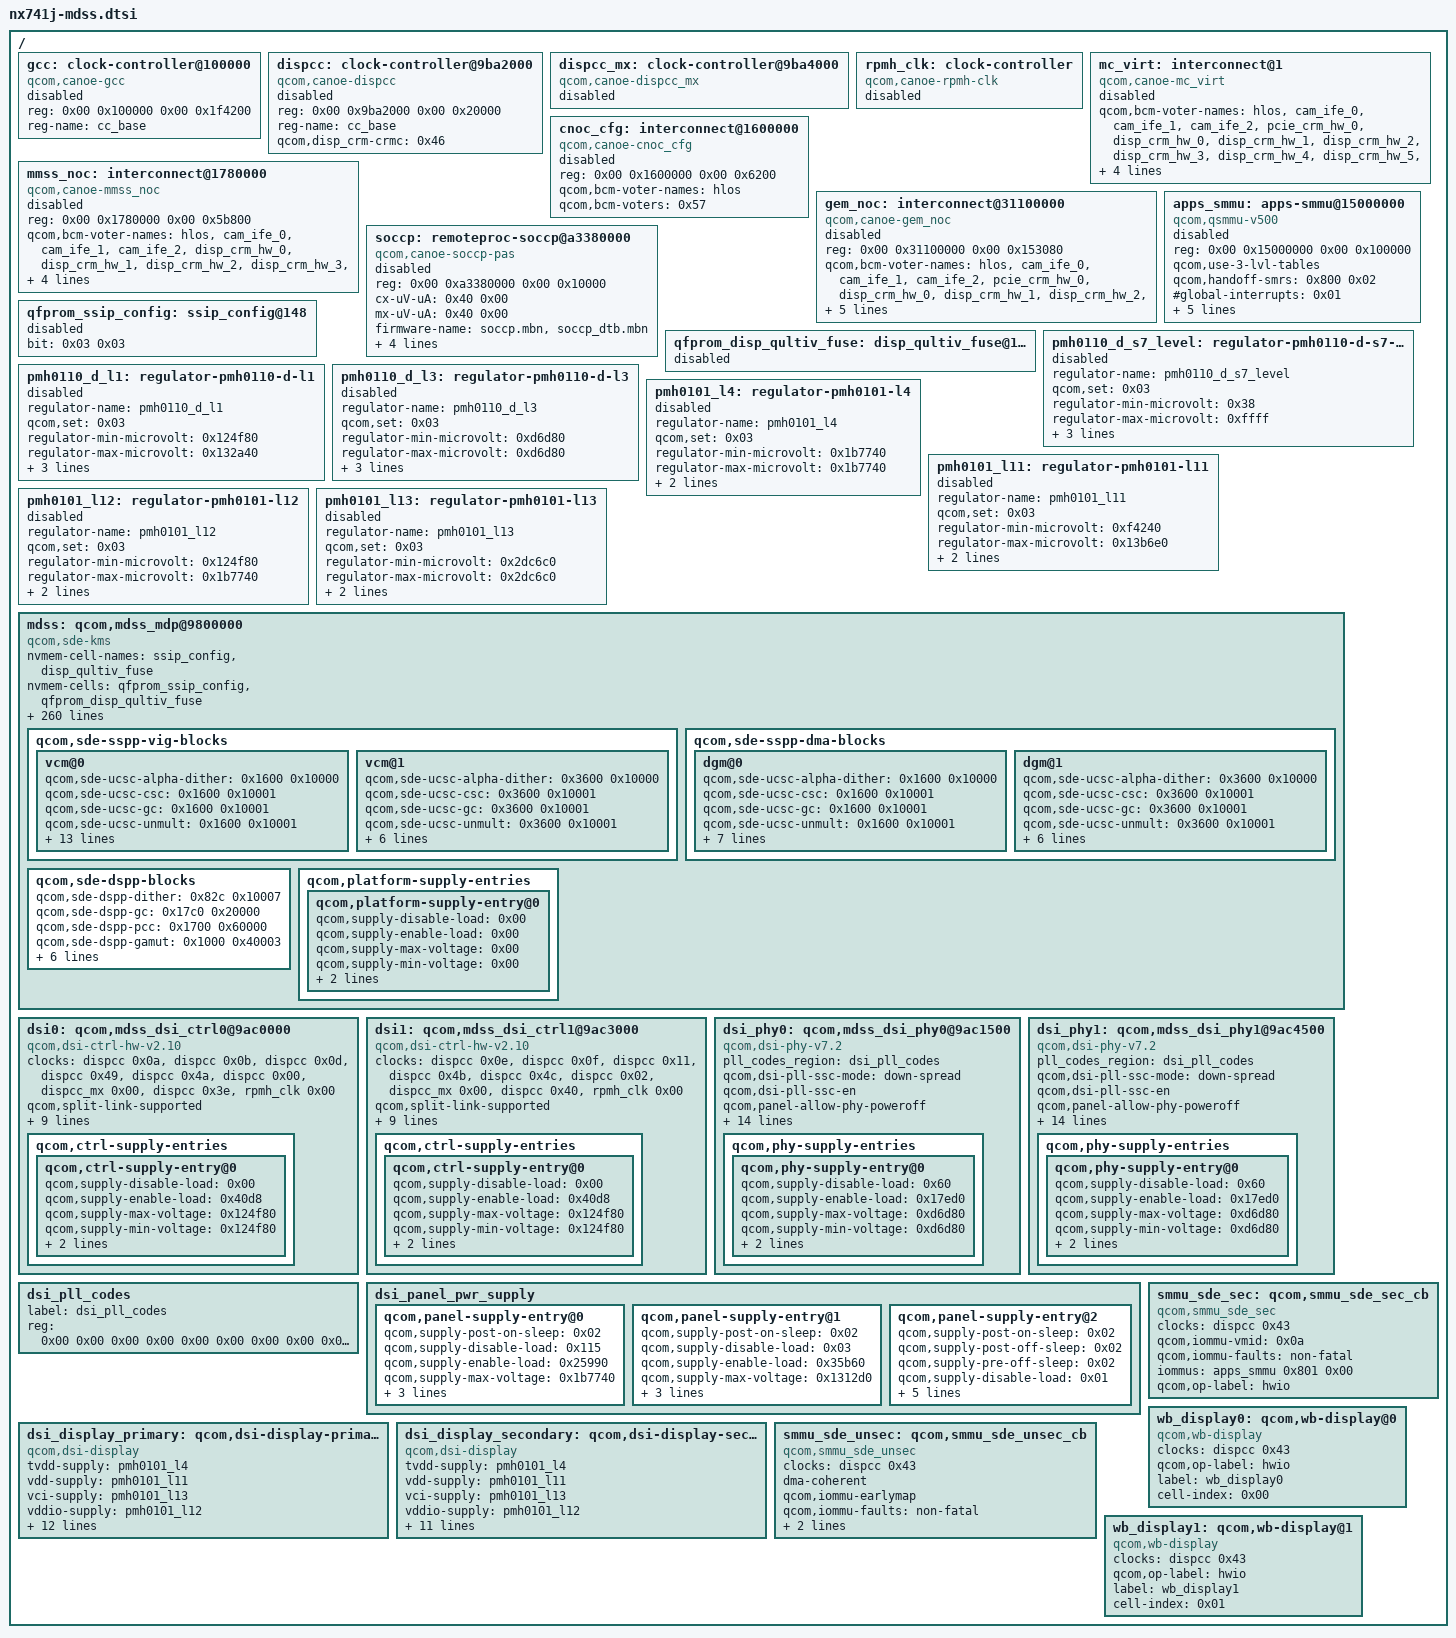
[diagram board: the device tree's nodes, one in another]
/*
 * Nubia Z80 Ultra (NX741J) MSM display controller (SDE/MDP + DSI).
 *
 * Generated by scripts/mk-mdss-dtsi.py from the device live FDT
 * (adb pull /sys/firmware/fdt); do not hand-edit, re-run the script instead.
 *
 * The stock tree keeps these nodes under /soc; they are placed at the root here
 * because sm8850.dtsi does not describe a /soc container yet.
 *
 * Providers outside the display block (GCC, DISPCC, RPMh clock, NoC, PMIC
 * regulators, qfprom cells, SMMU, SOCCP) are placeholders that carry the real
 * compatible/binding properties with status = "disabled": they exist so the
 * phandle lists keep their shape and the fragment compiles on its own.  Replace
 * them with the real driver nodes when those drivers are ported.
 *
 * Excluded on purpose: the DisplayPort connector (qcom,dp_display@9ad2000) and the
 * CESTA/HDCP block (qcom,sde_cesta@0x9bd8000) pull in the USB/alt-mode graph, so
 * their entries in mdss "connectors" are dropped; the TLMM pinctrl states of the
 * DSI connectors are dropped too (pinmux is a separate step).
 *
 * Nothing here is exported to the ADT yet: no node carries unixnu,adt-name.
 */

/ {
	/* ---- display providers (placeholders) ---- */
	/* stock: /soc/clock-controller@100000 */
	gcc: clock-controller@100000 {
		compatible = "qcom,canoe-gcc", "syscon";
		reg = <0x00 0x100000 0x00 0x1f4200>;
		reg-name = "cc_base";
		clock-names = "bi_tcxo", "pcie_0_pipe_clk", "sleep_clk", "ufs_phy_rx_symbol_0_clk",
				"ufs_phy_rx_symbol_1_clk", "ufs_phy_tx_symbol_0_clk", "usb3_phy_wrapper_gcc_usb30_pipe_clk";
		#clock-cells = <0x01>;
		#reset-cells = <0x01>;
		#power-domain-cells = <0x01>;
		status = "disabled";
	};
	/* stock: /soc/clock-controller@9ba2000 */
	dispcc: clock-controller@9ba2000 {
		compatible = "qcom,canoe-dispcc", "syscon";
		reg = <0x00 0x9ba2000 0x00 0x20000>;
		reg-name = "cc_base";
		clock-names = "bi_tcxo", "bi_tcxo_ao", "sleep_clk", "iface";
		qcom,disp_crm-crmc = <0x46>;
		#clock-cells = <0x01>;
		#power-domain-cells = <0x01>;
		#reset-cells = <0x01>;
		status = "disabled";
	};
	/* stock: /soc/clock-controller@9ba2000/clock-controller@9ba4000 */
	dispcc_mx: clock-controller@9ba4000 {
		compatible = "qcom,canoe-dispcc_mx";
		clock-names = "bi_tcxo", "sleep_clk";
		#clock-cells = <0x01>;
		status = "disabled";
	};
	/* stock: /soc/rsc@18900000/drv@2/clock-controller */
	rpmh_clk: clock-controller {
		compatible = "qcom,canoe-rpmh-clk";
		#clock-cells = <0x01>;
		status = "disabled";
	};
	/* stock: /soc/interconnect@1 */
	mc_virt: interconnect@1 {
		compatible = "qcom,canoe-mc_virt";
		#interconnect-cells = <0x01>;
		qcom,bcm-voter-names = "hlos", "cam_ife_0", "cam_ife_1", "cam_ife_2", "pcie_crm_hw_0",
				"disp_crm_hw_0", "disp_crm_hw_1", "disp_crm_hw_2", "disp_crm_hw_3", "disp_crm_hw_4",
				"disp_crm_hw_5", "disp_crm_hw_6", "disp_crm_hw_7", "disp_crm_hw_8", "disp_crm_sw_0";
		qcom,bcm-voters = <0x57 0x59 0x5a 0x5b 0x58 0x5c 0x5d 0x5e 0x5f 0x60 0x61 0x62 0x63 0x64 0x65>;
		status = "disabled";
	};
	/* stock: /soc/interconnect@1600000 */
	cnoc_cfg: interconnect@1600000 {
		compatible = "qcom,canoe-cnoc_cfg";
		reg = <0x00 0x1600000 0x00 0x6200>;
		#interconnect-cells = <0x01>;
		qcom,bcm-voter-names = "hlos";
		qcom,bcm-voters = <0x57>;
		status = "disabled";
	};
	/* stock: /soc/interconnect@1780000 */
	mmss_noc: interconnect@1780000 {
		compatible = "qcom,canoe-mmss_noc";
		reg = <0x00 0x1780000 0x00 0x5b800>;
		#interconnect-cells = <0x01>;
		qcom,bcm-voter-names = "hlos", "cam_ife_0", "cam_ife_1", "cam_ife_2", "disp_crm_hw_0",
				"disp_crm_hw_1", "disp_crm_hw_2", "disp_crm_hw_3", "disp_crm_hw_4", "disp_crm_hw_5",
				"disp_crm_hw_6", "disp_crm_hw_7", "disp_crm_hw_8", "disp_crm_sw_0";
		qcom,bcm-voters = <0x57 0x59 0x5a 0x5b 0x5c 0x5d 0x5e 0x5f 0x60 0x61 0x62 0x63 0x64 0x65>;
		status = "disabled";
	};
	/* stock: /soc/interconnect@31100000 */
	gem_noc: interconnect@31100000 {
		compatible = "qcom,canoe-gem_noc";
		reg = <0x00 0x31100000 0x00 0x153080>;
		#interconnect-cells = <0x01>;
		qcom,bcm-voter-names = "hlos", "cam_ife_0", "cam_ife_1", "cam_ife_2", "pcie_crm_hw_0",
				"disp_crm_hw_0", "disp_crm_hw_1", "disp_crm_hw_2", "disp_crm_hw_3", "disp_crm_hw_4",
				"disp_crm_hw_5", "disp_crm_hw_6", "disp_crm_hw_7", "disp_crm_hw_8", "disp_crm_sw_0";
		qcom,bcm-voters = <0x57 0x59 0x5a 0x5b 0x58 0x5c 0x5d 0x5e 0x5f 0x60 0x61 0x62 0x63 0x64 0x65>;
		status = "disabled";
	};
	/* stock: /soc/apps-smmu@15000000 */
	apps_smmu: apps-smmu@15000000 {
		compatible = "qcom,qsmmu-v500";
		reg = <0x00 0x15000000 0x00 0x100000>;
		#iommu-cells = <0x02>;
		qcom,use-3-lvl-tables;
		qcom,handoff-smrs = <0x800 0x02>;
		#global-interrupts = <0x01>;
		#size-cells = <0x02>;
		#address-cells = <0x02>;
		ranges;
		dma-coherent;
		interrupts = <0x00 0x41 0x04 0x00 0x61 0x04 0x00 0x62 0x04 0x00 0x63 0x04 0x00 0x64 0x04 0x00 0x65
				0x04 0x00 0x66 0x04 0x00 0x67 0x04 0x00 0x68 0x04 0x00 0x69 0x04 0x00 0x6a 0x04 0x00 0x6b 0x04 0x00
				0x6c 0x04 0x00 0x6d 0x04 0x00 0x6e 0x04 0x00 0x6f 0x04 0x00 0x70 0x04 0x00 0x71 0x04 0x00 0x72 0x04
				0x00 0x73 0x04 0x00 0x74 0x04 0x00 0x75 0x04 0x00 0x76 0x04 0x00 0xb5 0x04 0x00 0xb6 0x04 0x00 0xb7
				0x04 0x00 0xb8 0x04 0x00 0xb9 0x04 0x00 0xba 0x04 0x00 0xbb 0x04 0x00 0xbc 0x04 0x00 0xbd 0x04 0x00
				0xbe 0x04 0x00 0xbf 0x04 0x00 0xc0 0x04 0x00 0x13b 0x04 0x00 0x13c 0x04 0x00 0x13d 0x04 0x00 0x13e
				0x04 0x00 0x13f 0x04 0x00 0x140 0x04 0x00 0x141 0x04 0x00 0x142 0x04 0x00 0x143 0x04 0x00 0x144
				0x04 0x00 0x145 0x04 0x00 0x146 0x04 0x00 0x147 0x04 0x00 0x148 0x04 0x00 0x149 0x04 0x00 0x14a
				0x04 0x00 0x14b 0x04 0x00 0x14c 0x04 0x00 0x14d 0x04 0x00 0x14e 0x04 0x00 0x14f 0x04 0x00 0x150
				0x04 0x00 0x151 0x04 0x00 0x152 0x04 0x00 0x153 0x04 0x00 0x154 0x04 0x00 0x155 0x04 0x00 0x156
				0x04 0x00 0x157 0x04 0x00 0x158 0x04 0x00 0x159 0x04 0x00 0x18b 0x04 0x00 0x18c 0x04 0x00 0x18d
				0x04 0x00 0x18e 0x04 0x00 0x18f 0x04 0x00 0x190 0x04 0x00 0x191 0x04 0x00 0x192 0x04 0x00 0x193
				0x04 0x00 0x194 0x04 0x00 0x195 0x04 0x00 0x196 0x04 0x00 0x197 0x04 0x00 0x198 0x04 0x00 0x199
				0x04 0x00 0x1a2 0x04 0x00 0x1a3 0x04 0x00 0x19c 0x04 0x00 0x1a5 0x04 0x00 0x2c3 0x04 0x00 0x1a7
				0x04 0x00 0x1a8 0x04 0x00 0x1a9 0x04 0x00 0x2b2 0x04 0x00 0x2b3 0x04 0x00 0x2b4 0x04 0x00 0x2b5
				0x04 0x00 0x2b6 0x04 0x00 0x2b7 0x04 0x00 0x2b8 0x04 0x00 0x2b9 0x04 0x00 0x19a 0x04 0x00 0x1e8
				0x04 0x00 0x1e9 0x04 0x00 0x1ea 0x04 0x00 0x1eb 0x04 0x00 0x1ec 0x04 0x00 0x1ed 0x04 0x00 0x1ee
				0x04 0x00 0x1ef 0x04 0x00 0x1f0 0x04 0x00 0x1f1 0x04 0x00 0x1f2 0x04 0x00 0x1f3 0x04 0x00 0x1f4
				0x04 0x00 0x1f5 0x04 0x00 0x1f6 0x04>;
		qcom,actlr = <0x1800 0xc0 0x01 0x1820 0x00 0x01 0x1860 0x00 0x103 0x18a0 0x00 0x103 0x18e0 0x00 0x103
				0x1980 0x00 0x01 0x1c00 0x00 0x01 0xc01 0x40 0x303 0xc02 0x20 0x303 0xc03 0x40 0x303 0xc04 0x20
				0x303 0xc05 0x20 0x303 0xc06 0x20 0x303 0xc07 0x40 0x303 0xc08 0x20 0x303 0xc09 0x40 0x303 0xc0c
				0x40 0x303 0xc0d 0x40 0x303 0xc21 0x00 0x303 0xc23 0x00 0x303 0xc27 0x00 0x303 0xc29 0x00 0x303
				0xc2c 0x00 0x303 0xc2d 0x00 0x303 0xc42 0x00 0x303 0xc44 0x00 0x303 0xc45 0x00 0x303 0xc46 0x00
				0x303 0xc48 0x00 0x303 0x800 0x02 0x01 0x801 0x00 0x01 0x19a3 0x00 0x01 0x19a4 0x00 0x01 0x1900
				0x20 0x103 0x1904 0x20 0x103 0x1923 0x00 0x103 0x1940 0x00 0x103 0x1941 0x00 0x103 0x1943 0x00
				0x103 0x1944 0x00 0x103 0x1945 0x00 0x103 0x1946 0x00 0x103 0x1a20 0x00 0x103 0x1a21 0x00 0x103>;
		status = "disabled";
	};
	/* stock: /soc/remoteproc-soccp@a3380000 */
	soccp: remoteproc-soccp@a3380000 {
		compatible = "qcom,canoe-soccp-pas";
		reg = <0x00 0xa3380000 0x00 0x10000>;
		cx-uV-uA = <0x40 0x00>;
		mx-uV-uA = <0x40 0x00>;
		reg-names = "cx", "mx";
		clock-names = "xo";
		firmware-name = "soccp.mbn", "soccp_dtb.mbn";
		interrupt-names = "wdog", "fatal", "ready", "stop-ack", "handover", "pong", "wake-ack";
		qcom,smem-states = <0x6c 0x00 0x6c 0x0a 0x6c 0x09 0x6c 0x08>;
		qcom,smem-state-names = "stop", "wakeup", "sleep", "ping";
		status = "disabled";
	};
	/* stock: /soc/qfprom@221c8000/ssip_config@148 */
	qfprom_ssip_config: ssip_config@148 {
		bit = <0x03 0x03>;
		status = "disabled";
	};
	/* stock: /soc/qfprom@221c8000/disp_qultiv_fuse@144 */
	qfprom_disp_qultiv_fuse: disp_qultiv_fuse@144 {
		status = "disabled";
	};
	/* stock: /soc/rsc@18900000/drv@2/rpmh-regulator-mmcxlvl/regulator-pmh0110-d-s7-level */
	pmh0110_d_s7_level: regulator-pmh0110-d-s7-level {
		regulator-name = "pmh0110_d_s7_level";
		qcom,set = <0x03>;
		regulator-min-microvolt = <0x38>;
		regulator-max-microvolt = <0xffff>;
		qcom,init-voltage-level = <0x180>;
		qcom,proxy-consumer-enable;
		qcom,proxy-consumer-voltage = <0x180 0xffff>;
		status = "disabled";
	};
	/* stock: /soc/rsc@18900000/drv@2/rpmh-regulator-l1d-e0/regulator-pmh0110-d-l1 */
	pmh0110_d_l1: regulator-pmh0110-d-l1 {
		regulator-name = "pmh0110_d_l1";
		qcom,set = <0x03>;
		regulator-min-microvolt = <0x124f80>;
		regulator-max-microvolt = <0x132a40>;
		qcom,init-voltage = <0x124f80>;
		qcom,init-mode = <0x03>;
		qcom,proxy-consumer-enable;
		status = "disabled";
	};
	/* stock: /soc/rsc@18900000/drv@2/rpmh-regulator-l3d-e0/regulator-pmh0110-d-l3 */
	pmh0110_d_l3: regulator-pmh0110-d-l3 {
		regulator-name = "pmh0110_d_l3";
		qcom,set = <0x03>;
		regulator-min-microvolt = <0xd6d80>;
		regulator-max-microvolt = <0xd6d80>;
		qcom,init-voltage = <0xd6d80>;
		qcom,init-mode = <0x03>;
		qcom,proxy-consumer-enable;
		status = "disabled";
	};
	/* stock: /soc/rsc@18900000/drv@2/rpmh-regulator-l4b-e0/regulator-pmh0101-l4 */
	pmh0101_l4: regulator-pmh0101-l4 {
		regulator-name = "pmh0101_l4";
		qcom,set = <0x03>;
		regulator-min-microvolt = <0x1b7740>;
		regulator-max-microvolt = <0x1b7740>;
		qcom,init-voltage = <0x1b7740>;
		qcom,init-mode = <0x03>;
		status = "disabled";
	};
	/* stock: /soc/rsc@18900000/drv@2/rpmh-regulator-l11b-e0/regulator-pmh0101-l11 */
	pmh0101_l11: regulator-pmh0101-l11 {
		regulator-name = "pmh0101_l11";
		qcom,set = <0x03>;
		regulator-min-microvolt = <0xf4240>;
		regulator-max-microvolt = <0x13b6e0>;
		qcom,init-voltage = <0x1312d0>;
		qcom,init-mode = <0x03>;
		status = "disabled";
	};
	/* stock: /soc/rsc@18900000/drv@2/rpmh-regulator-l12b-e0/regulator-pmh0101-l12 */
	pmh0101_l12: regulator-pmh0101-l12 {
		regulator-name = "pmh0101_l12";
		qcom,set = <0x03>;
		regulator-min-microvolt = <0x124f80>;
		regulator-max-microvolt = <0x1b7740>;
		qcom,init-voltage = <0x1b7740>;
		qcom,init-mode = <0x03>;
		status = "disabled";
	};
	/* stock: /soc/rsc@18900000/drv@2/rpmh-regulator-l13b-e0/regulator-pmh0101-l13 */
	pmh0101_l13: regulator-pmh0101-l13 {
		regulator-name = "pmh0101_l13";
		qcom,set = <0x03>;
		regulator-min-microvolt = <0x2dc6c0>;
		regulator-max-microvolt = <0x2dc6c0>;
		qcom,init-voltage = <0x2dc6c0>;
		qcom,init-mode = <0x03>;
		status = "disabled";
	};

	/* ---- display controller ---- */
	mdss: qcom,mdss_mdp@9800000 {
		nvmem-cell-names = "ssip_config", "disp_qultiv_fuse";
		nvmem-cells = <&qfprom_ssip_config &qfprom_disp_qultiv_fuse>;
		qcom,sde-dspp-ltm-off = <0x3300 0x3300 0x3300 0x3300>;
		qcom,sde-dspp-ltm-version = <0x10004>;
		qcom,sde-ib-bw-vote = <0x2625a0 0x00 0xc3500>;
		qcom,sde-has-idle-pc;
		interconnect-names = "qcom,sde-data-bus0", "qcom,sde-ebi-bus", "qcom,sde-reg-bus";
		interconnects = <&mmss_noc 0x17 &gem_noc 0x22a &mc_virt 0x03 &mc_virt 0x200 &gem_noc 0x02 &cnoc_cfg
				0x207>;
		qcom,sde-soccp-controller = <&soccp>;
		qti,smmu-proxy-cb-id = <0x01>;
		qcom,sde-vm-exclude-reg-names = "ipcc_reg", "swfuse_phys";
		mmcx-supply = <&pmh0110_d_s7_level>;
		qcom,hw-fence-sw-version = <0x01>;
		clock-max-rate = <0x00 0x00 0x00 0x124f800 0x26be3680 0x26be3680>;
		clock-rate = <0x00 0x00 0x00 0x124f800 0x26be3680 0x26be3680>;
		clock-names = "gcc_bus", "iface_clk", "ahb_swi_clk", "vsync_clk", "lut_clk", "ssip_clk";
		clocks = <&gcc 0x0f &dispcc 0x06 &dispcc 0x08 &dispcc 0x52 &dispcc 0x46 &dispcc 0x47>;
		qcom,sde-reg-bus,vectors-KBps = <0x00 0x00 0x00 0x36b0 0x00 0x222e0 0x00 0x4baf0>;
		qcom,sde-secure-sid-mask = <0x2801 0x2c01>;
		qcom,sde-reg-dma-clk-ctrl = <0x2bc 0x14>;
		qcom,sde-reg-dma-xin-id = <0x07>;
		qcom,sde-reg-dma-trigger-off = <0x119c>;
		qcom,sde-reg-dma-version = <0x40000>;
		qcom,sde-reg-dma-id = <0x00 0x01>;
		qcom,sde-reg-dma-off = <0x00 0x800>;
		qcom,sde-ipcc-client-out-phys-id = <0x18>;
		qcom,sde-ipcc-protocol-offset = <0xc0000>;
		qcom,sde-hw-fence-mdp-ctl-offset = <0x4000>;
		qcom,sde-ipcc-client-dpu-phys-id = <0x15>;
		qcom,sde-ipcc-protocol-id = <0x04>;
		qcom,sde-qos-cpu-irq-latency = <0x12c>;
		qcom,sde-qos-cpu-dma-latency = <0x12c>;
		qcom,sde-qos-cpu-mask-performance = <0x03>;
		qcom,sde-qos-cpu-mask = <0x03>;
		qcom,sde-cdp-setting = <0x01 0x01 0x01 0x00>;
		qcom,sde-creq-lut = <0x112233 0x44556666 0x112233 0x66666666 0x112233 0x44556666 0x112233 0x66666666
				0x00 0x00 0x00 0x00 0x77776666 0x66666540 0x77776666 0x66666540 0x77776541 0x00 0x77776541 0x00
				0x112233 0x44556666 0x112233 0x66666666 0x112233 0x44556666 0x112233 0x66666666 0x00 0x00 0x00 0x00
				0x55555544 0x33221100 0x55555544 0x33221100>;
		qcom,sde-safe-lut = <0xff00 0xfff0 0xff00 0xfff0 0xffff 0xffff 0x01 0x01 0x3ff 0x3ff 0xff00 0xfff0
				0xff00 0xfff0 0xffff 0xffff 0xff 0xff>;
		qcom,sde-danger-lut = <0xffff 0xffff 0xffff 0xffff 0x00 0x00 0x00 0x00 0x00 0x00 0xffff 0xffff 0xffff
				0xffff 0x00 0x00 0xffff0000 0xffff0000>;
		qcom,sde-vbif-qos-wb-rot-remap = <0x04 0x04 0x05 0x05 0x05 0x05 0x05 0x06 0x04 0x04 0x05 0x05 0x05
				0x05 0x05 0x06>;
		qcom,sde-vbif-qos-cnoc-remap = <0x03 0x03 0x04 0x04 0x05 0x05 0x05 0x05 0x03 0x03 0x04 0x04 0x05 0x05
				0x05 0x05>;
		qcom,sde-vbif-qos-offline-wb-remap = <0x03 0x03 0x03 0x03 0x03 0x03 0x03 0x03 0x03 0x03 0x03 0x03
				0x03 0x03 0x03 0x03>;
		qcom,sde-vbif-qos-lutdma-remap = <0x04 0x04 0x04 0x04 0x05 0x05 0x05 0x05 0x04 0x04 0x04 0x04 0x05
				0x05 0x05 0x05>;
		qcom,sde-vbif-qos-cwb-remap = <0x04 0x04 0x05 0x05 0x05 0x05 0x05 0x06 0x04 0x04 0x05 0x05 0x05 0x05
				0x05 0x06>;
		qcom,sde-vbif-qos-nrt-remap = <0x03 0x03 0x03 0x03 0x03 0x03 0x03 0x03 0x03 0x03 0x03 0x03 0x03 0x03
				0x03 0x03>;
		qcom,sde-vbif-qos-rt-remap = <0x04 0x04 0x05 0x05 0x05 0x05 0x05 0x06 0x04 0x04 0x05 0x05 0x05 0x05
				0x05 0x06>;
		qcom,sde-vbif-dynamic-ot-wr-limit = <0x3b53800 0x02 0x76a7000 0x06 0x1da9c000 0x10>;
		qcom,sde-vbif-default-ot-wr-limit = <0x20>;
		qcom,sde-vbif-default-ot-rd-limit = <0x28>;
		qcom,sde-vbif-memtype-1 = <0x03 0x03 0x03 0x03 0x03 0x03 0x03 0x03>;
		qcom,sde-vbif-memtype-0 = <0x03 0x03 0x03 0x03 0x03 0x03 0x03 0x03>;
		qcom,sde-vbif-id = <0x00>;
		qcom,sde-vbif-size = <0x1074>;
		qcom,sde-vbif-off = <0x00>;
		qcom,sde-uidle-size = <0x80>;
		qcom,sde-uidle-off = <0x6000>;
		qcom,sde-lm-noise-version = <0x10000>;
		qcom,sde-lm-noise-off = <0x320>;
		qcom,sde-dspp-spr-dither-off = <0x34e0 0x34e0 0x34e0 0x34e0>;
		qcom,sde-dspp-spr-dither-version = <0x20000>;
		qcom,sde-dspp-spr-version = <0x20000>;
		qcom,sde-dspp-spr-size = <0x200>;
		qcom,sde-dspp-spr-off = <0x3400 0x3400 0x3400 0x3400>;
		qcom,sde-num-nrt-paths = <0x00>;
		qcom,sde-dram-channels = <0x04>;
		qcom,sde-min-dram-ib-kbps = "", "\f5";
		qcom,sde-min-llcc-ib-kbps = <0x00>;
		qcom,sde-min-core-ib-kbps = <0x2625a0>;
		qcom,sde-max-bw-high-kbps = <0x1ccd0c0>;
		qcom,sde-max-bw-low-kbps = <0x14689c0>;
		qcom,sde-max-trusted-vm-displays = <0x01>;
		qcom,sde-has-dest-scaler;
		qcom,sde-has-dim-layer;
		qcom,sde-pipe-order-version = <0x01>;
		qcom,sde-has-src-split;
		qcom,sde-has-cdp;
		qcom,sde-panic-per-pipe;
		qcom,sde-smart-panel-align-mode = <0x0c>;
		qcom,sde-macrotile-mode = <0x01>;
		qcom,sde-ubwc-static = <0x01>;
		qcom,sde-ubwc-bw-calc-version = <0x01>;
		qcom,sde-ubwc-swizzle = <0x06>;
		qcom,sde-ubwc-version = <0x60000000>;
		qcom,sde-highest-bank-bit = <0x08 0x03 0x07 0x02>;
		qcom,sde-mixer-blendstages = <0x0b>;
		qcom,sde-wb-linewidth-linear = <0x2000>;
		qcom,sde-max-dest-scaler-output-linewidth = <0xa00>;
		qcom,sde-max-dest-scaler-input-linewidth = <0x800>;
		qcom,sde-dsc-linewidth = <0xa00>;
		qcom,sde-wb-linewidth = <0x1000>;
		qcom,sde-sspp-linewidth = <0x1400>;
		qcom,sde-mixer-linewidth = <0xa00>;
		qcom,sde-qseed-scalar-version = <0x3005>;
		qcom,sde-qseed-sw-lib-rev = "qseedv3lite";
		qcom,sde-csc-type = "csc-10bit";
		qcom,sde-sspp-csc-off = <0x1800>;
		qcom,sde-sspp-clk-status = <0x4334 0x00 0x6334 0x00 0x8334 0x00 0xa334 0x00 0x24334 0x00 0x26334 0x00
				0x28334 0x00 0x2a334 0x00 0x2c334 0x00 0x2e334 0x00>;
		qcom,sde-sspp-clk-ctrl = <0x4330 0x00 0x6330 0x00 0x8330 0x00 0xa330 0x00 0x24330 0x00 0x26330 0x00
				0x28330 0x00 0x2a330 0x00 0x2c330 0x00 0x2e330 0x00>;
		qcom,sde-max-per-pipe-bw-high-kbps = <0x6c5660 0x6c5660 0x6c5660 0x6c5660 0x6c5660 0x6c5660 0x6c5660
				0x6c5660 0x6c5660 0x6c5660>;
		qcom,sde-max-per-pipe-bw-kbps = <0x44aa20 0x44aa20 0x44aa20 0x44aa20 0x44aa20 0x44aa20 0x44aa20
				0x44aa20 0x44aa20 0x44aa20>;
		qcom,sde-mixer-blend-op-off = <0x40 0x70 0xa0 0xd0 0x100 0x130 0x160 0x190 0x1c0 0x1f0 0x220>;
		qcom,sde-mixer-pair-mask = <0x02 0x01 0x04 0x03 0x06 0x05 0x08 0x07 0x0a 0x09 0x0c 0x0b>;
		qcom,sde-smart-dma-rev = "smart_dma_v2p5";
		qcom,sde-sspp-smart-dma-priority = <0x07 0x08 0x09 0x0a 0x01 0x02 0x03 0x04 0x05 0x06>;
		qcom,sde-sspp-excl-rect = <0x01 0x01 0x01 0x01 0x01 0x01 0x01 0x01 0x01 0x01>;
		qcom,sde-sspp-xin-id = <0x00 0x04 0x08 0x0c 0x01 0x05 0x09 0x0d 0x0e 0x0f>;
		qcom,sde-sspp-src-size = <0x84>;
		qcom,sde-sspp-off = <0x2c000 0x35000 0x3e000 0x47000 0x98000 0xa1000 0xaa000 0xb3000 0xbc000 0xc5000>;
		qcom,sde-sspp-type = "vig", "vig", "vig", "vig", "dma", "dma", "dma", "dma", "dma", "dma";
		qcom,sde-dither-size = <0x24>;
		qcom,sde-dither-version = <0x30000>;
		qcom,sde-cwb-dither = <0x00 0x00 0x00 0x00 0x00 0x00 0x00 0x00 0x01 0x01 0x01 0x01>;
		qcom,sde-dither-off = <0xc0 0xc0 0xc0 0xc0 0xc0 0xc0 0xc0 0xc0 0xc0 0xc0 0xc0 0xc0>;
		qcom,sde-dsc-native422-supp = <0x01 0x01 0x01 0x01 0x01 0x01 0x01 0x01>;
		qcom,sde-dsc-ctl-size = <0x24>;
		qcom,sde-dsc-ctl = <0xf00 0xf80 0xf00 0xf80 0xf00 0xf80 0xf00 0xf80>;
		qcom,sde-dsc-enc-size = <0x100>;
		qcom,sde-dsc-enc = <0x100 0x200 0x100 0x200 0x100 0x200 0x100 0x200>;
		qcom,sde-dsc-hw-rev = "dsc_1_2";
		qcom,sde-dsc-pair-mask = <0x02 0x01 0x04 0x03 0x06 0x05 0x08 0x07>;
		qcom,sde-dsc-size = <0x08>;
		qcom,sde-dsc-off = <0x182000 0x182000 0x184000 0x184000 0x186000 0x186000 0x188000 0x188000>;
		qcom,sde-cdm-size = <0x240>;
		qcom,sde-cdm-off = <0x19e000>;
		qcom,sde-pp-cwb = <0x00 0x00 0x00 0x00 0x00 0x00 0x00 0x00 0x01 0x01 0x01 0x01>;
		qcom,sde-merge-3d-size = <0x1c>;
		qcom,sde-merge-3d-off = <0x164000 0x165000 0x166000 0x167000 0x16a700 0x16b700>;
		qcom,sde-pp-merge-3d-id = <0x00 0x00 0x01 0x01 0x02 0x02 0x03 0x03 0x04 0x04 0x05 0x05>;
		qcom,sde-pp-size = <0x2c>;
		qcom,sde-pp-slave = <0x00 0x00 0x00 0x00 0x00 0x00 0x00 0x00 0x00 0x00 0x00 0x00>;
		qcom,sde-pp-off = <0x109000 0x111000 0x119000 0x121000 0x129000 0x131000 0x139000 0x141000 0x16a000
				0x16a400 0x16b000 0x16b400>;
		qcom,sde-intf-tear-irq-off = <0x00 0x18f800 0x190800 0x00>;
		qcom,sde-intf-type = "dp", "dsi", "dsi", "dp";
		qcom,sde-intf-size = <0x4bc>;
		qcom,sde-intf-off = <0x18e000 0x18f000 0x190000 0x191000>;
		qcom,sde-wb-id = <0x01 0x02>;
		qcom,sde-wb-xin-id = <0x0a 0x06>;
		qcom,sde-wb-size = <0x2c8>;
		qcom,sde-wb-off = <0x16e000 0x16f000>;
		qcom,sde-dest-scaler-size = <0x800>;
		qcom,sde-dest-scaler-off = <0x00 0x8000 0x10000 0x18000>;
		qcom,sde-dest-scaler-top-size = <0x1c>;
		qcom,sde-dest-scaler-top-off = <0x108000>;
		qcom,sde-dnsc-blur-dither-size = <0x40>;
		qcom,sde-dnsc-blur-dither-off = <0x5c0>;
		qcom,sde-dnsc-blur-gaus-lut-size = <0x400>;
		qcom,sde-dnsc-blur-gaus-lut-off = <0x100>;
		qcom,sde-dnsc-blur-size = <0x40>;
		qcom,sde-dnsc-blur-off = <0x1aa000>;
		qcom,sde-dnsc-blur-version = <0x100>;
		qcom,sde-aiqe-has-feature-aiscaler;
		qcom,sde-aiqe-has-feature-copr;
		qcom,sde-aiqe-has-feature-ssrc;
		qcom,sde-aiqe-has-feature-abc;
		qcom,sde-aiqe-has-feature-mdnie;
		qcom,sde-dspp-aiqe-aiscaler-size = <0x7d0>;
		qcom,sde-dspp-aiqe-aiscaler-version = <0x10000>;
		qcom,sde-dspp-aiqe-aiscaler-off = <0xbb000 0xffffffff>;
		qcom,sde-dspp-aiqe-wrapper-size = <0x1c>;
		qcom,sde-dspp-aiqe-wrapper-version = <0x10000>;
		qcom,sde-dspp-aiqe-wrapper-off = <0xc1780 0xffffffff 0xb2780 0xffffffff>;
		qcom,sde-dspp-aiqe-dither-size = <0x20>;
		qcom,sde-dspp-aiqe-dither-version = <0x10000>;
		qcom,sde-dspp-aiqe-dither-off = <0xc1700 0xffffffff 0xb2700 0xffffffff>;
		qcom,sde-dspp-aiqe-size = <0x474>;
		qcom,sde-dspp-aiqe-version = <0x20000>;
		qcom,sde-dspp-aiqe-off = <0xc1000 0xffffffff 0xb2000 0xffffffff>;
		qcom,sde-dspp-demura-version = <0x40000>;
		qcom,sde-dspp-demura-size = <0x154>;
		qcom,sde-dspp-demura-off = <0x3600 0x3600 0x3600 0x3600>;
		qcom,sde-dspp-rc-min-region-width = <0x14>;
		qcom,sde-dspp-rc-mem-size = <0xaa0>;
		qcom,sde-dspp-rc-size = <0x5c>;
		qcom,sde-dspp-rc-off = <0x3800 0x3800 0x3800 0x3800>;
		qcom,sde-dspp-rc-version = <0x10001>;
		qcom,sde-dspp-size = <0x1800>;
		qcom,sde-dspp-off = <0x106000 0x10e000 0x116000 0x11e000>;
		qcom,sde-dspp-top-size = <0x8c>;
		qcom,sde-dspp-top-off = <0x1300>;
		qcom,sde-mixer-dcwb-pref = "none", "none", "none", "none", "none", "none", "none", "none", "dcwb",
				"dcwb", "dcwb", "dcwb";
		qcom,sde-mixer-display-pref = "primary", "primary", "none", "none", "none", "none", "none", "none",
				"none", "none", "none", "none";
		qcom,sde-mixer-size = <0x400>;
		qcom,sde-mixer-off = <0x104000 0x10c000 0x114000 0x11c000 0x124000 0x12c000 0x134000 0x13c000 0xf0f
				0xf0f 0xf0f 0xf0f>;
		qcom,sde-ctl-hyp-size = <0xc00>;
		qcom,sde-ctl-hyp-off = <0x3000>;
		qcom,sde-ctl-display-pref = "primary", "none", "none", "none", "none", "none";
		qcom,sde-ctl-size = <0x1000>;
		qcom,sde-ctl-off = <0x20000 0x21000 0x22000 0x23000 0x24000 0x25000>;
		qcom,sde-qultiv-sw-version = <0x01>;
		qcom,sde-len = <0x488>;
		qcom,sde-off = <0x1000>;
		#cooling-cells = <0x02>;
		#interrupt-cells = <0x01>;
		interrupt-controller;
		interrupts = <0x00 0x53 0x04>;
		reg-names = "mdp_phys", "vbif_phys", "regdma_phys", "ipcc_reg", "swfuse_phys";
		reg = <0x00 0x9800000 0x00 0x1c8800 0x00 0x9b16000 0x00 0x2008 0x00 0x9b60000 0x00 0x7000 0x00
				0x1100000 0x00 0x1000 0x00 0x9aa0000 0x00 0x13c>;
		qcom,sde-hw-version = <0xd0000000>;
		status = "ok";
		qcom,op-label = "hwio";
		compatible = "qcom,sde-kms";
		connectors = <&dsi_display_primary &dsi_display_secondary &smmu_sde_unsec &smmu_sde_sec &wb_display0
				&wb_display1>;
		qcom,sde-sspp-vig-blocks {
			vcm@0 {
				qcom,sde-ucsc-alpha-dither = <0x1600 0x10000>;
				qcom,sde-ucsc-csc = <0x1600 0x10001>;
				qcom,sde-ucsc-gc = <0x1600 0x10001>;
				qcom,sde-ucsc-unmult = <0x1600 0x10001>;
				qcom,sde-ucsc-igc = <0x1600 0x10001>;
				qcom,sde-fp16-csc = <0x1150 0x10000>;
				qcom,sde-fp16-gc = <0x1150 0x10000>;
				qcom,sde-fp16-unmult = <0x1150 0x10000>;
				qcom,sde-fp16-igc = <0x1150 0x10000>;
				qcom,sde-vig-inverse-pma;
				qcom,sde-vig-igc = <0x1c00 0x60000>;
				qcom,sde-vig-gamut = <0x1c00 0x60001>;
				qcom,sde-vig-qseed-size = <0xec>;
				qcom,sde-vig-qseed-off = <0x2000>;
				qcom,sde-vig-csc-off = <0x1800>;
				qcom,sde-vig-top-off = <0x1600>;
				cell-index = <0x00>;
			};
			vcm@1 {
				qcom,sde-ucsc-alpha-dither = <0x3600 0x10000>;
				qcom,sde-ucsc-csc = <0x3600 0x10001>;
				qcom,sde-ucsc-gc = <0x3600 0x10001>;
				qcom,sde-ucsc-unmult = <0x3600 0x10001>;
				qcom,sde-ucsc-igc = <0x3600 0x10001>;
				qcom,sde-fp16-csc = <0x3150 0x10000>;
				qcom,sde-fp16-gc = <0x3150 0x10000>;
				qcom,sde-fp16-unmult = <0x3150 0x10000>;
				qcom,sde-fp16-igc = <0x3150 0x10000>;
				cell-index = <0x01>;
			};
		};
		qcom,sde-sspp-dma-blocks {
			dgm@0 {
				qcom,sde-ucsc-alpha-dither = <0x1600 0x10000>;
				qcom,sde-ucsc-csc = <0x1600 0x10001>;
				qcom,sde-ucsc-gc = <0x1600 0x10001>;
				qcom,sde-ucsc-unmult = <0x1600 0x10001>;
				qcom,sde-ucsc-igc = <0x1600 0x10001>;
				qcom,sde-fp16-csc = <0x1150 0x10000>;
				qcom,sde-fp16-gc = <0x1150 0x10000>;
				qcom,sde-fp16-unmult = <0x1150 0x10000>;
				qcom,sde-fp16-igc = <0x1150 0x10000>;
				qcom,sde-dma-top-off = <0x1600>;
				cell-index = <0x00>;
			};
			dgm@1 {
				qcom,sde-ucsc-alpha-dither = <0x3600 0x10000>;
				qcom,sde-ucsc-csc = <0x3600 0x10001>;
				qcom,sde-ucsc-gc = <0x3600 0x10001>;
				qcom,sde-ucsc-unmult = <0x3600 0x10001>;
				qcom,sde-ucsc-igc = <0x3600 0x10001>;
				qcom,sde-fp16-csc = <0x3150 0x10000>;
				qcom,sde-fp16-gc = <0x3150 0x10000>;
				qcom,sde-fp16-unmult = <0x3150 0x10000>;
				qcom,sde-fp16-igc = <0x3150 0x10000>;
				cell-index = <0x01>;
			};
		};
		qcom,sde-dspp-blocks {
			qcom,sde-dspp-dither = <0x82c 0x10007>;
			qcom,sde-dspp-gc = <0x17c0 0x20000>;
			qcom,sde-dspp-pcc = <0x1700 0x60000>;
			qcom,sde-dspp-gamut = <0x1000 0x40003>;
			qcom,sde-dspp-vlut = <0xa00 0x10008>;
			qcom,sde-dspp-sixzone = <0x900 0x20000>;
			qcom,sde-dspp-hist = <0x800 0x10007>;
			qcom,sde-dspp-memcolor = <0x880 0x10007>;
			qcom,sde-dspp-hsic = <0x800 0x10007>;
			qcom,sde-dspp-igc = <0x1260 0x50001>;
		};
		qcom,platform-supply-entries {
			#size-cells = <0x00>;
			#address-cells = <0x01>;
			qcom,platform-supply-entry@0 {
				qcom,supply-disable-load = <0x00>;
				qcom,supply-enable-load = <0x00>;
				qcom,supply-max-voltage = <0x00>;
				qcom,supply-min-voltage = <0x00>;
				qcom,supply-name = "mmcx";
				reg = <0x00>;
			};
		};
	};
	dsi0: qcom,mdss_dsi_ctrl0@9ac0000 {
		clock-names = "byte_clk", "byte_clk_rcg", "byte_intf_clk", "pixel_clk", "pixel_clk_rcg", "esync_clk",
				"osc_clk", "esc_clk", "xo";
		clocks = <&dispcc 0x0a &dispcc 0x0b &dispcc 0x0d &dispcc 0x49 &dispcc 0x4a &dispcc 0x00 &dispcc_mx
				0x00 &dispcc 0x3e &rpmh_clk 0x00>;
		qcom,split-link-supported;
		vdda-1p2-supply = <&pmh0110_d_l1>;
		interrupts = <0x04 0x00>;
		interrupt-parent = <&mdss>;
		reg-names = "dsi_ctrl", "disp_cc_base", "mdp_intf_base";
		reg = <0x00 0x9ac0000 0x00 0x1000 0x00 0x9bb1000 0x00 0x04 0x00 0x998f000 0x00 0x300>;
		frame-threshold-time-us = <0x320>;
		cell-index = <0x00>;
		label = "dsi-ctrl-0";
		status = "ok";
		qcom,op-label = "hwio";
		compatible = "qcom,dsi-ctrl-hw-v2.10";
		#address-cells = <1>;
		#size-cells = <0>;
		qcom,ctrl-supply-entries {
			#size-cells = <0x00>;
			#address-cells = <0x01>;
			qcom,ctrl-supply-entry@0 {
				qcom,supply-disable-load = <0x00>;
				qcom,supply-enable-load = <0x40d8>;
				qcom,supply-max-voltage = <0x124f80>;
				qcom,supply-min-voltage = <0x124f80>;
				qcom,supply-name = "vdda-1p2";
				reg = <0x00>;
			};
		};
	};
	dsi1: qcom,mdss_dsi_ctrl1@9ac3000 {
		clock-names = "byte_clk", "byte_clk_rcg", "byte_intf_clk", "pixel_clk", "pixel_clk_rcg", "esync_clk",
				"osc_clk", "esc_clk", "xo";
		clocks = <&dispcc 0x0e &dispcc 0x0f &dispcc 0x11 &dispcc 0x4b &dispcc 0x4c &dispcc 0x02 &dispcc_mx
				0x00 &dispcc 0x40 &rpmh_clk 0x00>;
		qcom,split-link-supported;
		vdda-1p2-supply = <&pmh0110_d_l1>;
		interrupts = <0x05 0x00>;
		interrupt-parent = <&mdss>;
		reg-names = "dsi_ctrl", "disp_cc_base", "mdp_intf_base";
		reg = <0x00 0x9ac3000 0x00 0x1000 0x00 0x9bb1000 0x00 0x04 0x00 0x9990000 0x00 0x300>;
		frame-threshold-time-us = <0x320>;
		cell-index = <0x01>;
		label = "dsi-ctrl-1";
		status = "ok";
		qcom,op-label = "hwio";
		compatible = "qcom,dsi-ctrl-hw-v2.10";
		#address-cells = <1>;
		#size-cells = <0>;
		qcom,ctrl-supply-entries {
			#size-cells = <0x00>;
			#address-cells = <0x01>;
			qcom,ctrl-supply-entry@0 {
				qcom,supply-disable-load = <0x00>;
				qcom,supply-enable-load = <0x40d8>;
				qcom,supply-max-voltage = <0x124f80>;
				qcom,supply-min-voltage = <0x124f80>;
				qcom,supply-name = "vdda-1p2";
				reg = <0x00>;
			};
		};
	};
	dsi_phy0: qcom,mdss_dsi_phy0@9ac1500 {
		pll_codes_region = <&dsi_pll_codes>;
		qcom,dsi-pll-ssc-mode = "down-spread";
		qcom,dsi-pll-ssc-en;
		qcom,panel-allow-phy-poweroff;
		vdda-0p9-supply = <&pmh0110_d_l3>;
		qcom,platform-regulator-settings = [1d 1d 1d 1d 1d];
		qcom,platform-lane-config = <0xa0a 0xa0a 0xa0a 0xa0a 0x8a8a>;
		qcom,platform-strength-ctrl = [55 03 55 03 55 03 55 03 55 00];
		qcom,mdp = <&mdss>;
		pll-label = "dsi_pll_3nm";
		reg-names = "dsi_phy", "pll_base", "dyn_refresh_base";
		reg = <0x00 0x9ac1000 0x00 0xa00 0x00 0x9ac1500 0x00 0x400 0x00 0x9ac0200 0x00 0xa0>;
		#clock-cells = <0x01>;
		cell-index = <0x00>;
		label = "dsi-phy-0";
		status = "ok";
		qcom,op-label = "hwio";
		compatible = "qcom,dsi-phy-v7.2";
		qcom,phy-supply-entries {
			#size-cells = <0x00>;
			#address-cells = <0x01>;
			qcom,phy-supply-entry@0 {
				qcom,supply-disable-load = <0x60>;
				qcom,supply-enable-load = <0x17ed0>;
				qcom,supply-max-voltage = <0xd6d80>;
				qcom,supply-min-voltage = <0xd6d80>;
				qcom,supply-name = "vdda-0p9";
				reg = <0x00>;
			};
		};
	};
	dsi_phy1: qcom,mdss_dsi_phy1@9ac4500 {
		pll_codes_region = <&dsi_pll_codes>;
		qcom,dsi-pll-ssc-mode = "down-spread";
		qcom,dsi-pll-ssc-en;
		qcom,panel-allow-phy-poweroff;
		vdda-0p9-supply = <&pmh0110_d_l3>;
		qcom,platform-lane-config = <0xa0a 0xa0a 0xa0a 0xa0a 0x8a8a>;
		qcom,platform-regulator-settings = [1d 1d 1d 1d 1d];
		qcom,platform-strength-ctrl = [55 03 55 03 55 03 55 03 55 00];
		qcom,mdp = <&mdss>;
		pll-label = "dsi_pll_3nm";
		reg-names = "dsi_phy", "pll_base", "dyn_refresh_base";
		reg = <0x00 0x9ac4000 0x00 0xa00 0x00 0x9ac4500 0x00 0x400 0x00 0x9ac3200 0x00 0xa0>;
		#clock-cells = <0x01>;
		cell-index = <0x01>;
		label = "dsi-phy-1";
		status = "ok";
		qcom,op-label = "hwio";
		compatible = "qcom,dsi-phy-v7.2";
		qcom,phy-supply-entries {
			#size-cells = <0x00>;
			#address-cells = <0x01>;
			qcom,phy-supply-entry@0 {
				qcom,supply-disable-load = <0x60>;
				qcom,supply-enable-load = <0x17ed0>;
				qcom,supply-max-voltage = <0xd6d80>;
				qcom,supply-min-voltage = <0xd6d80>;
				qcom,supply-name = "vdda-0p9";
				reg = <0x00>;
			};
		};
	};
	dsi_pll_codes: dsi_pll_codes {
		label = "dsi_pll_codes";
		reg = <0x00 0x00 0x00 0x00 0x00 0x00 0x00 0x00 0x00 0x00 0x00 0x00 0x00 0x00 0x00 0x00 0x00 0x00 0x00
				0x00 0x00 0x00 0x00 0x00 0x00 0x00 0x00 0x00 0x00 0x00 0x00 0x00 0x00 0x00 0x00 0x00 0x00 0x00 0x00
				0x00 0x00 0x00 0x00 0x00 0x00 0x00 0x00 0x00 0x00 0x00 0x00 0x00 0x00 0x00 0x00 0x00 0x00 0x00 0x00
				0x00 0x00 0x00 0x00 0x00 0x00 0x00 0x00 0x00 0x00 0x00 0x00 0x00 0x00 0x00 0x00 0x00 0x00 0x00 0x00
				0x00 0x00 0x00 0x00 0x00 0x00 0x00 0x00 0x00 0x00 0x00 0x00 0x00 0x00 0x00 0x00 0x00 0x00 0x00 0x00
				0x00 0x00 0x00 0x00 0x00 0x00 0x00 0x00 0x00 0x00 0x00 0x00 0x00 0x00 0x00 0x00 0x00 0x00 0x00 0x00
				0x00 0x00 0x00 0x00 0x00 0x00 0x00 0x00 0x00>;
		#size-cells = <0x00>;
		#address-cells = <0x01>;
	};
	dsi_panel_pwr_supply: dsi_panel_pwr_supply {
		#size-cells = <0x00>;
		#address-cells = <0x01>;
		qcom,panel-supply-entry@0 {
			qcom,supply-post-on-sleep = <0x02>;
			qcom,supply-disable-load = <0x115>;
			qcom,supply-enable-load = <0x25990>;
			qcom,supply-max-voltage = <0x1b7740>;
			qcom,supply-min-voltage = <0x1b7740>;
			qcom,supply-name = "vddio";
			reg = <0x00>;
		};
		qcom,panel-supply-entry@1 {
			qcom,supply-post-on-sleep = <0x02>;
			qcom,supply-disable-load = <0x03>;
			qcom,supply-enable-load = <0x35b60>;
			qcom,supply-max-voltage = <0x1312d0>;
			qcom,supply-min-voltage = <0x1312d0>;
			qcom,supply-name = "vdd";
			reg = <0x01>;
		};
		qcom,panel-supply-entry@2 {
			qcom,supply-post-on-sleep = <0x02>;
			qcom,supply-post-off-sleep = <0x02>;
			qcom,supply-pre-off-sleep = <0x02>;
			qcom,supply-disable-load = <0x01>;
			qcom,supply-enable-load = <0x2710>;
			qcom,supply-max-voltage = <0x2dc6c0>;
			qcom,supply-min-voltage = <0x2dc6c0>;
			qcom,supply-name = "vci";
			reg = <0x02>;
		};
	};
	dsi_display_primary: qcom,dsi-display-primary {
		/* pinctrl-3 = <0x7c2 0x7c3 0x7bb 0x7bc 0x7bd 0x7be 0x7bf>;  -- TLMM pin state, see nx741j-hw.dtsi */
		/* pinctrl-2 = <0x7b9 0x7c1 0x7c0 0x7bc 0x7bd 0x7be 0x7bf>;  -- TLMM pin state, see nx741j-hw.dtsi */
		/* pinctrl-1 = <0x7b9 0x7ba 0x7c0 0x7bc 0x7bd 0x7be 0x7bf>;  -- TLMM pin state, see nx741j-hw.dtsi */
		/* pinctrl-0 = <0x7b9 0x7ba 0x7bb 0x7bc 0x7bd 0x7be 0x7bf>;  -- TLMM pin state, see nx741j-hw.dtsi */
		/* pinctrl-names = "panel_active", "panel_active_with_esync", "panel_active_with_esync_without_te", "pan...;  -- only meaningful together with pinctrl-0..3 */
		tvdd-supply = <&pmh0101_l4>;
		vdd-supply = <&pmh0101_l11>;
		vci-supply = <&pmh0101_l13>;
		vddio-supply = <&pmh0101_l12>;
		clock-names = "pll_byte_clk0", "pll_dsi_clk0", "pll_byte_clk1", "pll_dsi_clk1", "mdp_core_clk",
				"esync_clk_rcg";
		clocks = <&dsi_phy0 0x00 &dsi_phy0 0x01 &dsi_phy1 0x00 &dsi_phy1 0x01 &dispcc 0x43 &dispcc 0x01>;
		qcom,demura-panel-id = <0x122e700 0x471>;
		qcom,dsi-default-panel = <&panel>;
		qcom,mdp = <&mdss>;
		qcom,panel-te-source = <0x00>;
		qcom,platform-te-gpio = <&tlmm 0x56 0x00>;
		qcom,dsi-phy = <&dsi_phy0 &dsi_phy1>;
		qcom,dsi-ctrl = <&dsi0 &dsi1>;
		status = "ok";
		qcom,op-label = "hwio";
		label = "primary";
		compatible = "qcom,dsi-display";
	};
	dsi_display_secondary: qcom,dsi-display-secondary {
		/* pinctrl-3 = <0x7c9 0x7ca 0x7c6>;  -- TLMM pin state, see nx741j-hw.dtsi */
		/* pinctrl-2 = <0x7c4 0x7c8 0x7c7>;  -- TLMM pin state, see nx741j-hw.dtsi */
		/* pinctrl-1 = <0x7c4 0x7c5 0x7c7>;  -- TLMM pin state, see nx741j-hw.dtsi */
		/* pinctrl-0 = <0x7c4 0x7c5 0x7c6>;  -- TLMM pin state, see nx741j-hw.dtsi */
		/* pinctrl-names = "panel_active", "panel_active_with_esync", "panel_active_with_esync_without_te", "pan...;  -- only meaningful together with pinctrl-0..3 */
		tvdd-supply = <&pmh0101_l4>;
		vdd-supply = <&pmh0101_l11>;
		vci-supply = <&pmh0101_l13>;
		vddio-supply = <&pmh0101_l12>;
		clock-names = "pll_byte_clk0", "pll_dsi_clk0", "pll_byte_clk1", "pll_dsi_clk1", "mdp_core_clk",
				"esync_clk_rcg";
		clocks = <&dsi_phy0 0x00 &dsi_phy0 0x01 &dsi_phy1 0x00 &dsi_phy1 0x01 &dispcc 0x43 &dispcc 0x03>;
		qcom,demura-panel-id = <0x00 0x00>;
		qcom,mdp = <&mdss>;
		qcom,panel-te-source = <0x01>;
		qcom,platform-te-gpio = <&tlmm 0x57 0x00>;
		qcom,dsi-phy = <&dsi_phy0 &dsi_phy1>;
		qcom,dsi-ctrl = <&dsi0 &dsi1>;
		status = "ok";
		qcom,op-label = "hwio";
		label = "secondary";
		compatible = "qcom,dsi-display";
	};
	smmu_sde_unsec: qcom,smmu_sde_unsec_cb {
		clock-names = "mdp_core_clk";
		clocks = <&dispcc 0x43>;
		dma-coherent;
		qcom,iommu-earlymap;
		qcom,iommu-faults = "non-fatal";
		/* memory-region = <0x668>;  -- reserved-memory region, not modelled yet */
		iommus = <&apps_smmu 0x800 0x02>;
		status = "ok";
		qcom,op-label = "hwio";
		compatible = "qcom,smmu_sde_unsec";
	};
	smmu_sde_sec: qcom,smmu_sde_sec_cb {
		clock-names = "mdp_core_clk";
		clocks = <&dispcc 0x43>;
		qcom,iommu-vmid = <0x0a>;
		qcom,iommu-faults = "non-fatal";
		/* memory-region = <0x668>;  -- reserved-memory region, not modelled yet */
		iommus = <&apps_smmu 0x801 0x00>;
		status = "ok";
		qcom,op-label = "hwio";
		compatible = "qcom,smmu_sde_sec";
	};
	wb_display0: qcom,wb-display@0 {
		clock-names = "mdp_core_clk";
		clocks = <&dispcc 0x43>;
		status = "ok";
		qcom,op-label = "hwio";
		label = "wb_display0";
		cell-index = <0x00>;
		compatible = "qcom,wb-display";
	};
	wb_display1: qcom,wb-display@1 {
		clock-names = "mdp_core_clk";
		clocks = <&dispcc 0x43>;
		status = "ok";
		qcom,op-label = "hwio";
		label = "wb_display1";
		cell-index = <0x01>;
		compatible = "qcom,wb-display";
	};
};
